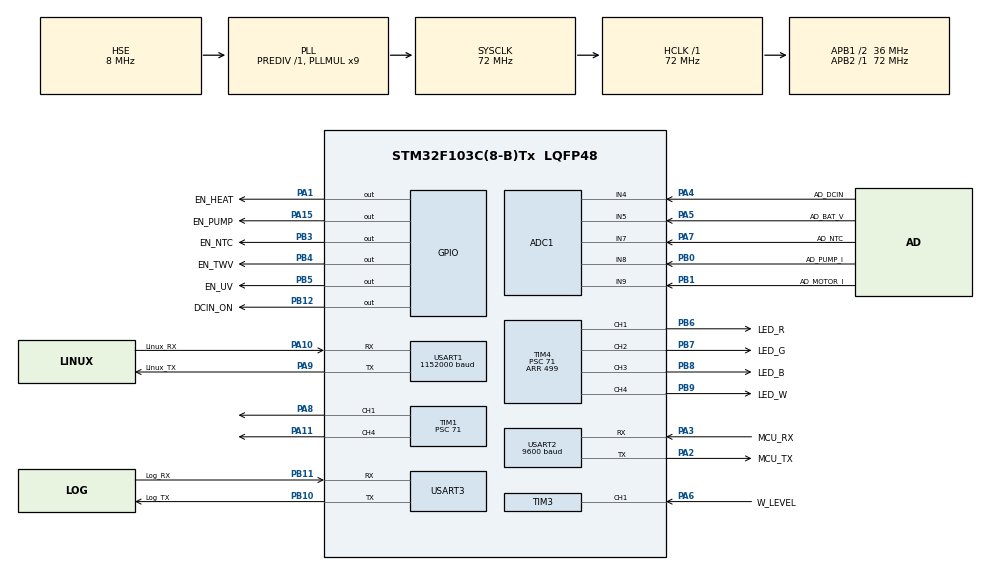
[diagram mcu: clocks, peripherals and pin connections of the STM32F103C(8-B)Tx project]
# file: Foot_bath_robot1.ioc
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ADC1.Channel-0\#ChannelRegularConversion=ADC_CHANNEL_4
ADC1.Channel-1\#ChannelRegularConversion=ADC_CHANNEL_5
ADC1.Channel-2\#ChannelRegularConversion=ADC_CHANNEL_7
ADC1.Channel-3\#ChannelRegularConversion=ADC_CHANNEL_8
ADC1.Channel-4\#ChannelRegularConversion=ADC_CHANNEL_9
ADC1.ContinuousConvMode=ENABLE
ADC1.DataAlign=ADC_DATAALIGN_RIGHT
ADC1.NbrOfConversion=5
ADC1.NbrOfConversionFlag=1
ADC1.Rank-0\#ChannelRegularConversion=1
ADC1.Rank-1\#ChannelRegularConversion=2
ADC1.Rank-2\#ChannelRegularConversion=3
ADC1.Rank-3\#ChannelRegularConversion=4
ADC1.Rank-4\#ChannelRegularConversion=5
ADC1.SamplingTime-0\#ChannelRegularConversion=ADC_SAMPLETIME_71CYCLES_5
ADC1.SamplingTime-1\#ChannelRegularConversion=ADC_SAMPLETIME_71CYCLES_5
ADC1.SamplingTime-2\#ChannelRegularConversion=ADC_SAMPLETIME_71CYCLES_5
ADC1.SamplingTime-3\#ChannelRegularConversion=ADC_SAMPLETIME_71CYCLES_5
ADC1.SamplingTime-4\#ChannelRegularConversion=ADC_SAMPLETIME_71CYCLES_5
ADC1.master=1
Dma.ADC1.0.Direction=DMA_PERIPH_TO_MEMORY
Dma.ADC1.0.Instance=DMA1_Channel1
Dma.ADC1.0.MemDataAlignment=DMA_MDATAALIGN_HALFWORD
Dma.ADC1.0.MemInc=DMA_MINC_ENABLE
Dma.ADC1.0.Mode=DMA_CIRCULAR
Dma.ADC1.0.PeriphDataAlignment=DMA_PDATAALIGN_HALFWORD
Dma.ADC1.0.PeriphInc=DMA_PINC_DISABLE
Dma.ADC1.0.Priority=DMA_PRIORITY_LOW
Dma.Request0=ADC1
Dma.Request1=USART1_RX
Dma.Request2=USART1_TX
Dma.Request3=USART2_TX
Dma.Request4=USART2_RX
Dma.Request5=USART3_TX
Dma.USART1_RX.1.Direction=DMA_PERIPH_TO_MEMORY
Dma.USART1_RX.1.Instance=DMA1_Channel5
Dma.USART1_RX.1.MemDataAlignment=DMA_MDATAALIGN_BYTE
Dma.USART1_RX.1.MemInc=DMA_MINC_ENABLE
Dma.USART1_RX.1.Mode=DMA_CIRCULAR
Dma.USART1_RX.1.PeriphDataAlignment=DMA_PDATAALIGN_BYTE
Dma.USART1_RX.1.PeriphInc=DMA_PINC_DISABLE
Dma.USART1_RX.1.Priority=DMA_PRIORITY_LOW
Dma.USART1_TX.2.Direction=DMA_MEMORY_TO_PERIPH
Dma.USART1_TX.2.Instance=DMA1_Channel4
Dma.USART1_TX.2.MemDataAlignment=DMA_MDATAALIGN_BYTE
Dma.USART1_TX.2.MemInc=DMA_MINC_ENABLE
Dma.USART1_TX.2.Mode=DMA_NORMAL
Dma.USART1_TX.2.PeriphDataAlignment=DMA_PDATAALIGN_BYTE
Dma.USART1_TX.2.PeriphInc=DMA_PINC_DISABLE
Dma.USART1_TX.2.Priority=DMA_PRIORITY_LOW
Dma.USART2_RX.4.Direction=DMA_PERIPH_TO_MEMORY
Dma.USART2_RX.4.Instance=DMA1_Channel6
Dma.USART2_RX.4.MemDataAlignment=DMA_MDATAALIGN_BYTE
Dma.USART2_RX.4.MemInc=DMA_MINC_ENABLE
Dma.USART2_RX.4.Mode=DMA_CIRCULAR
Dma.USART2_RX.4.PeriphDataAlignment=DMA_PDATAALIGN_BYTE
Dma.USART2_RX.4.PeriphInc=DMA_PINC_DISABLE
Dma.USART2_RX.4.Priority=DMA_PRIORITY_LOW
Dma.USART2_TX.3.Direction=DMA_MEMORY_TO_PERIPH
Dma.USART2_TX.3.Instance=DMA1_Channel7
Dma.USART2_TX.3.MemDataAlignment=DMA_MDATAALIGN_BYTE
Dma.USART2_TX.3.MemInc=DMA_MINC_ENABLE
Dma.USART2_TX.3.Mode=DMA_NORMAL
Dma.USART2_TX.3.PeriphDataAlignment=DMA_PDATAALIGN_BYTE
Dma.USART2_TX.3.PeriphInc=DMA_PINC_DISABLE
Dma.USART2_TX.3.Priority=DMA_PRIORITY_LOW
Dma.USART3_TX.5.Direction=DMA_MEMORY_TO_PERIPH
Dma.USART3_TX.5.Instance=DMA1_Channel2
Dma.USART3_TX.5.MemDataAlignment=DMA_MDATAALIGN_BYTE
Dma.USART3_TX.5.MemInc=DMA_MINC_ENABLE
Dma.USART3_TX.5.Mode=DMA_NORMAL
Dma.USART3_TX.5.PeriphDataAlignment=DMA_PDATAALIGN_BYTE
Dma.USART3_TX.5.PeriphInc=DMA_PINC_DISABLE
Dma.USART3_TX.5.Priority=DMA_PRIORITY_LOW
FREERTOS.Tasks01=Task1,40,256,Sensor_Task,Default,NULL,Dynamic,NULL,NULL;Task2,40,256,Temp_Control_Task,Default,NULL,Dynamic,NULL,NULL;Task3,24,256,Motor_Task,Default,NULL,Dynamic,NULL,NULL;Task4,24,256,Pump_Valve_Task,Default,NULL,Dynamic,NULL,NULL;Task5,8,128,UV_Lamp_Task,Default,NULL,Dynamic,NULL,NULL;Task6,24,256,Communication_Task,Default,NULL,Dynamic,NULL,NULL;Task7,8,128,Logging_Task,Default,NULL,Dynamic,NULL,NULL;Task8,40,128,System_Monitor_Task,Default,NULL,Dynamic,NULL,NULL
FREERTOS.configTOTAL_HEAP_SIZE=10240
Mcu.Family=STM32F1
Mcu.Name=STM32F103C(8-B)Tx
Mcu.Package=LQFP48
NVIC.ADC1_2_IRQn=true\:6\:0\:true\:false\:true\:true\:true\:true\:true
NVIC.DMA1_Channel1_IRQn=true\:6\:0\:true\:false\:true\:true\:false\:true\:true
NVIC.DMA1_Channel2_IRQn=true\:6\:0\:true\:false\:true\:true\:false\:true\:true
NVIC.DMA1_Channel4_IRQn=true\:6\:0\:true\:false\:true\:true\:false\:true\:true
NVIC.DMA1_Channel5_IRQn=true\:6\:0\:true\:false\:true\:true\:false\:true\:true
NVIC.DMA1_Channel6_IRQn=true\:6\:0\:true\:false\:true\:true\:false\:true\:true
NVIC.DMA1_Channel7_IRQn=true\:6\:0\:true\:false\:true\:true\:false\:true\:true
NVIC.PriorityGroup=NVIC_PRIORITYGROUP_4
NVIC.TIM2_IRQn=true\:15\:0\:false\:false\:true\:false\:false\:true\:true
NVIC.TIM3_IRQn=true\:6\:0\:true\:false\:true\:true\:true\:true\:true
NVIC.TimeBase=TIM2_IRQn
NVIC.TimeBaseIP=TIM2
NVIC.USART1_IRQn=true\:5\:0\:true\:false\:true\:true\:true\:true\:true
NVIC.USART2_IRQn=true\:5\:0\:true\:false\:true\:true\:true\:true\:true
NVIC.USART3_IRQn=true\:6\:0\:true\:false\:true\:true\:true\:true\:true
PA1.GPIO_Label=EN_HEAT
PA1.GPIO_Speed=GPIO_SPEED_FREQ_MEDIUM
PA1.Signal=GPIO_Output
PA10.GPIO_Label=Linux_RX
PA10.Mode=Asynchronous
PA10.Signal=USART1_RX
PA11.Signal=S_TIM1_CH4
PA13.Mode=Serial_Wire
PA13.Signal=SYS_JTMS-SWDIO
PA14.Mode=Serial_Wire
PA14.Signal=SYS_JTCK-SWCLK
PA15.GPIO_Label=EN_PUMP
PA15.GPIO_Speed=GPIO_SPEED_FREQ_MEDIUM
PA15.Signal=GPIO_Output
PA2.GPIO_Label=MCU_TX
PA2.Mode=Asynchronous
PA2.Signal=USART2_TX
PA3.GPIO_Label=MCU_RX
PA3.GPIO_PuPd=GPIO_PULLUP
PA3.Mode=Asynchronous
PA3.Signal=USART2_RX
PA4.GPIO_Label=AD_DCIN
PA4.Signal=ADCx_IN4
PA5.GPIO_Label=AD_BAT_V
PA5.Signal=ADCx_IN5
PA6.GPIO_Label=W_LEVEL
PA6.Signal=S_TIM3_CH1
PA7.GPIO_Label=AD_NTC
PA7.Signal=ADCx_IN7
PA8.Signal=S_TIM1_CH1
PA9.GPIO_Label=Linux_TX
PA9.Mode=Asynchronous
PA9.Signal=USART1_TX
PB0.GPIO_Label=AD_PUMP_I
PB0.Signal=ADCx_IN8
PB1.GPIO_Label=AD_MOTOR_I
PB1.Signal=ADCx_IN9
PB10.GPIO_Label=Log_TX
PB10.Mode=Asynchronous
PB10.Signal=USART3_TX
PB11.GPIO_Label=Log_RX
PB11.Mode=Asynchronous
PB11.Signal=USART3_RX
PB12.GPIO_Label=DCIN_ON
PB12.GPIO_Speed=GPIO_SPEED_FREQ_MEDIUM
PB12.Signal=GPIO_Output
PB3.GPIO_Label=EN_NTC
PB3.GPIO_Speed=GPIO_SPEED_FREQ_MEDIUM
PB3.Signal=GPIO_Output
PB4.GPIO_Label=EN_TWV
PB4.GPIO_Speed=GPIO_SPEED_FREQ_MEDIUM
PB4.Signal=GPIO_Output
PB5.GPIO_Label=EN_UV
PB5.GPIO_Speed=GPIO_SPEED_FREQ_MEDIUM
PB5.Signal=GPIO_Output
PB6.GPIO_Label=LED_R 
PB6.Signal=S_TIM4_CH1
PB7.GPIO_Label=LED_G 
PB7.Signal=S_TIM4_CH2
PB8.GPIO_Label=LED_B 
PB8.Signal=S_TIM4_CH3
PB9.GPIO_Label=LED_W 
PB9.Signal=S_TIM4_CH4
PD0-OSC_IN.Mode=HSE-External-Oscillator
PD0-OSC_IN.Signal=RCC_OSC_IN
PD1-OSC_OUT.Mode=HSE-External-Oscillator
PD1-OSC_OUT.Signal=RCC_OSC_OUT
ProjectManager.HeapSize=0x200
ProjectManager.StackSize=0x400
ProjectManager.TargetToolchain=MDK-ARM V5.32
RCC.ADCPresc=RCC_ADCPCLK2_DIV6
RCC.AHBFreq_Value=72000000
RCC.APB1CLKDivider=RCC_HCLK_DIV2
RCC.APB1Freq_Value=36000000
RCC.APB1TimFreq_Value=72000000
RCC.APB2Freq_Value=72000000
RCC.APB2TimFreq_Value=72000000
RCC.HCLKFreq_Value=72000000
RCC.PLLMUL=RCC_PLL_MUL9
RCC.PLLSourceVirtual=RCC_PLLSOURCE_HSE
RCC.SYSCLKFreq_VALUE=72000000
RCC.SYSCLKSource=RCC_SYSCLKSOURCE_PLLCLK
RCC.USBFreq_Value=72000000
SH.ADCx_IN4.0=ADC1_IN4,IN4
SH.ADCx_IN5.0=ADC1_IN5,IN5
SH.ADCx_IN7.0=ADC1_IN7,IN7
SH.ADCx_IN8.0=ADC1_IN8,IN8
SH.ADCx_IN9.0=ADC1_IN9,IN9
SH.S_TIM1_CH1.0=TIM1_CH1,PWM Generation1 CH1
SH.S_TIM1_CH4.0=TIM1_CH4,PWM Generation4 CH4
SH.S_TIM3_CH1.0=TIM3_CH1,Input_Capture1_from_TI1
SH.S_TIM4_CH1.0=TIM4_CH1,PWM Generation1 CH1
SH.S_TIM4_CH2.0=TIM4_CH2,PWM Generation2 CH2
SH.S_TIM4_CH3.0=TIM4_CH3,PWM Generation3 CH3
SH.S_TIM4_CH4.0=TIM4_CH4,PWM Generation4 CH4
TIM1.Channel-PWM\ Generation1\ CH1=TIM_CHANNEL_1
TIM1.Channel-PWM\ Generation4\ CH4=TIM_CHANNEL_4
TIM1.Period=999
TIM1.Prescaler=71
TIM3.Channel-Input_Capture1_from_TI1=TIM_CHANNEL_1
TIM3.Period=65535
TIM3.Prescaler=7
TIM4.Channel-PWM\ Generation1\ CH1=TIM_CHANNEL_1
TIM4.Channel-PWM\ Generation2\ CH2=TIM_CHANNEL_2
TIM4.Channel-PWM\ Generation3\ CH3=TIM_CHANNEL_3
TIM4.Channel-PWM\ Generation4\ CH4=TIM_CHANNEL_4
TIM4.Period=499
TIM4.Prescaler=71
USART1.BaudRate=1152000
USART1.VirtualMode=VM_ASYNC
USART2.BaudRate=9600
USART2.VirtualMode=VM_ASYNC
USART3.VirtualMode=VM_ASYNC
VP_FREERTOS_VS_CMSIS_V2.Mode=CMSIS_V2
VP_SYS_VS_tim2.Mode=TIM2
board=custom

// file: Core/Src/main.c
/* USER CODE BEGIN Header */
/**
  ******************************************************************************
  * @file           : main.c
  * @brief          : Main program body
  ******************************************************************************
  * @attention
  *
  * Copyright (c) 2026 STMicroelectronics.
  * All rights reserved.
  *
  * This software is licensed under terms that can be found in the LICENSE file
  * in the root directory of this software component.
  * If no LICENSE file comes with this software, it is provided AS-IS.
  *
  ******************************************************************************
  */
/* USER CODE END Header */
#include "main.h"
#include "cmsis_os.h"
#include "adc.h"
#include "dma.h"
#include "tim.h"
#include "usart.h"
#include "gpio.h"

void SystemClock_Config(void);
void MX_FREERTOS_Init(void);

int main(void)
{

  /* MCU Configuration--------------------------------------------------------*/

  /* Reset of all peripherals, Initializes the Flash interface and the Systick. */
  HAL_Init();

  /* USER CODE BEGIN Init */
	__HAL_AFIO_REMAP_SWJ_NOJTAG();
  /* USER CODE END Init */

  /* Configure the system clock */
  SystemClock_Config();

  /* Initialize all configured peripherals */
  MX_GPIO_Init();
  MX_DMA_Init();
  MX_ADC1_Init();
  MX_USART1_UART_Init();
  MX_USART2_UART_Init();
  MX_USART3_UART_Init();
  MX_TIM3_Init();
  MX_TIM4_Init();
  MX_TIM1_Init();

  /* Init scheduler */
  osKernelInitialize();  /* Call init function for freertos objects (in cmsis_os2.c) */
  MX_FREERTOS_Init();

  /* Start scheduler */
  osKernelStart();

  /* We should never get here as control is now taken by the scheduler */

  /* Infinite loop */
  while (1)
  {

  }
}

void SystemClock_Config(void)
{
  RCC_OscInitTypeDef RCC_OscInitStruct = {0};
  RCC_ClkInitTypeDef RCC_ClkInitStruct = {0};
  RCC_PeriphCLKInitTypeDef PeriphClkInit = {0};

  /** Initializes the RCC Oscillators according to the specified parameters
  * in the RCC_OscInitTypeDef structure.
  */
  RCC_OscInitStruct.OscillatorType = RCC_OSCILLATORTYPE_HSE;
  RCC_OscInitStruct.HSEState = RCC_HSE_ON;
  RCC_OscInitStruct.HSEPredivValue = RCC_HSE_PREDIV_DIV1;
  RCC_OscInitStruct.HSIState = RCC_HSI_ON;
  RCC_OscInitStruct.PLL.PLLState = RCC_PLL_ON;
  RCC_OscInitStruct.PLL.PLLSource = RCC_PLLSOURCE_HSE;
  RCC_OscInitStruct.PLL.PLLMUL = RCC_PLL_MUL9;
  if (HAL_RCC_OscConfig(&RCC_OscInitStruct) != HAL_OK)
  {
    Error_Handler();
  }

  /** Initializes the CPU, AHB and APB buses clocks
  */
  RCC_ClkInitStruct.ClockType = RCC_CLOCKTYPE_HCLK|RCC_CLOCKTYPE_SYSCLK
                              |RCC_CLOCKTYPE_PCLK1|RCC_CLOCKTYPE_PCLK2;
  RCC_ClkInitStruct.SYSCLKSource = RCC_SYSCLKSOURCE_PLLCLK;
  RCC_ClkInitStruct.AHBCLKDivider = RCC_SYSCLK_DIV1;
  RCC_ClkInitStruct.APB1CLKDivider = RCC_HCLK_DIV2;
  RCC_ClkInitStruct.APB2CLKDivider = RCC_HCLK_DIV1;

  if (HAL_RCC_ClockConfig(&RCC_ClkInitStruct, FLASH_LATENCY_2) != HAL_OK)
  {
    Error_Handler();
  }
  PeriphClkInit.PeriphClockSelection = RCC_PERIPHCLK_ADC;
  PeriphClkInit.AdcClockSelection = RCC_ADCPCLK2_DIV6;
  if (HAL_RCCEx_PeriphCLKConfig(&PeriphClkInit) != HAL_OK)
  {
    Error_Handler();
  }
}

void HAL_TIM_PeriodElapsedCallback(TIM_HandleTypeDef *htim)
{
  if (htim->Instance == TIM2)
  {
    HAL_IncTick();
  }
}

void Error_Handler(void)
{
  __disable_irq();
  while (1)
  {
  }
}

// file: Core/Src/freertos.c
/* USER CODE BEGIN Header */
/**
  ******************************************************************************
  * File Name          : freertos.c
  * Description        : Code for freertos applications
  ******************************************************************************
  * @attention
  *
  * Copyright (c) 2026 STMicroelectronics.
  * All rights reserved.
  *
  * This software is licensed under terms that can be found in the LICENSE file
  * in the root directory of this software component.
  * If no LICENSE file comes with this software, it is provided AS-IS.
  *
  ******************************************************************************
  */
/* USER CODE END Header */

#include "FreeRTOS.h"
#include "task.h"
#include "main.h"
#include "cmsis_os.h"

/* USER CODE BEGIN Includes */
#include "app_bucket.h"
#include "rtos_tasks.h"

/* USER CODE END Includes */

/* Definitions for Task1 */
osThreadId_t Task1Handle;
const osThreadAttr_t Task1_attributes = {
  .name = "Task1",
  .stack_size = 256 * 4,
  .priority = (osPriority_t) osPriorityHigh,
};
/* Definitions for Task2 */
osThreadId_t Task2Handle;
const osThreadAttr_t Task2_attributes = {
  .name = "Task2",
  .stack_size = 256 * 4,
  .priority = (osPriority_t) osPriorityHigh,
};
/* Definitions for Task3 */
osThreadId_t Task3Handle;
const osThreadAttr_t Task3_attributes = {
  .name = "Task3",
  .stack_size = 256 * 4,
  .priority = (osPriority_t) osPriorityNormal,
};
/* Definitions for Task4 */
osThreadId_t Task4Handle;
const osThreadAttr_t Task4_attributes = {
  .name = "Task4",
  .stack_size = 256 * 4,
  .priority = (osPriority_t) osPriorityNormal,
};
/* Definitions for Task5 */
osThreadId_t Task5Handle;
const osThreadAttr_t Task5_attributes = {
  .name = "Task5",
  .stack_size = 128 * 4,
  .priority = (osPriority_t) osPriorityLow,
};
/* Definitions for Task6 */
osThreadId_t Task6Handle;
const osThreadAttr_t Task6_attributes = {
  .name = "Task6",
  .stack_size = 256 * 4,
  .priority = (osPriority_t) osPriorityNormal,
};
/* Definitions for Task7 */
osThreadId_t Task7Handle;
const osThreadAttr_t Task7_attributes = {
  .name = "Task7",
  .stack_size = 512 * 4,
  .priority = (osPriority_t) osPriorityLow,
};
/* Definitions for Task8 */
osThreadId_t Task8Handle;
const osThreadAttr_t Task8_attributes = {
  .name = "Task8",
  .stack_size = 128 * 4,
  .priority = (osPriority_t) osPriorityHigh,
};

void Sensor_Task(void *argument);
void Temp_Control_Task(void *argument);
void Motor_Task(void *argument);
void Pump_Valve_Task(void *argument);
void UV_Lamp_Task(void *argument);
void Communication_Task(void *argument);
void Logging_Task(void *argument);
void System_Monitor_Task(void *argument);

void MX_FREERTOS_Init(void); /* (MISRA C 2004 rule 8.1) */

void MX_FREERTOS_Init(void) {
  /* USER CODE BEGIN Init */
  BucketApp_Init();

  //水泵运放电路调试
  //HAL_GPIO_WritePin(EN_PUMP_GPIO_Port, EN_PUMP_Pin, GPIO_PIN_SET);
  /* USER CODE END Init */

  /* Create the thread(s) */
  /* creation of Task1 */
  Task1Handle = osThreadNew(Sensor_Task, NULL, &Task1_attributes);

  /* creation of Task2 */
  Task2Handle = osThreadNew(Temp_Control_Task, NULL, &Task2_attributes);

  /* creation of Task3 */
  Task3Handle = osThreadNew(Motor_Task, NULL, &Task3_attributes);

  /* creation of Task4 */
  Task4Handle = osThreadNew(Pump_Valve_Task, NULL, &Task4_attributes);

  /* creation of Task5 */
  Task5Handle = osThreadNew(UV_Lamp_Task, NULL, &Task5_attributes);

  /* creation of Task6 */
  Task6Handle = osThreadNew(Communication_Task, NULL, &Task6_attributes);

  /* creation of Task7 */
  Task7Handle = osThreadNew(Logging_Task, NULL, &Task7_attributes);

  /* creation of Task8 */
  Task8Handle = osThreadNew(System_Monitor_Task, NULL, &Task8_attributes);

}

void Sensor_Task(void *argument)
{
  /* USER CODE BEGIN Sensor_Task */
  RtosTasks_Sensor(argument);
  /* USER CODE END Sensor_Task */
}

void Temp_Control_Task(void *argument)
{
  /* USER CODE BEGIN Temp_Control_Task */
  RtosTasks_TempControl(argument);
  /* USER CODE END Temp_Control_Task */
}

void Motor_Task(void *argument)
{
  /* USER CODE BEGIN Motor_Task */
  RtosTasks_Motor(argument);
  /* USER CODE END Motor_Task */
}

void Pump_Valve_Task(void *argument)
{
  /* USER CODE BEGIN Pump_Valve_Task */
  RtosTasks_PumpValve(argument);
  /* USER CODE END Pump_Valve_Task */
}

void UV_Lamp_Task(void *argument)
{
  /* USER CODE BEGIN UV_Lamp_Task */
  RtosTasks_UvLamp(argument);
  /* USER CODE END UV_Lamp_Task */
}

void Communication_Task(void *argument)
{
  /* USER CODE BEGIN Communication_Task */
  RtosTasks_Communication(argument);
  /* USER CODE END Communication_Task */
}

void Logging_Task(void *argument)
{
  /* USER CODE BEGIN Logging_Task */
  RtosTasks_Logging(argument);
  /* USER CODE END Logging_Task */
}

void System_Monitor_Task(void *argument)
{
  /* USER CODE BEGIN System_Monitor_Task */
  RtosTasks_SystemMonitor(argument);
  /* USER CODE END System_Monitor_Task */
}
